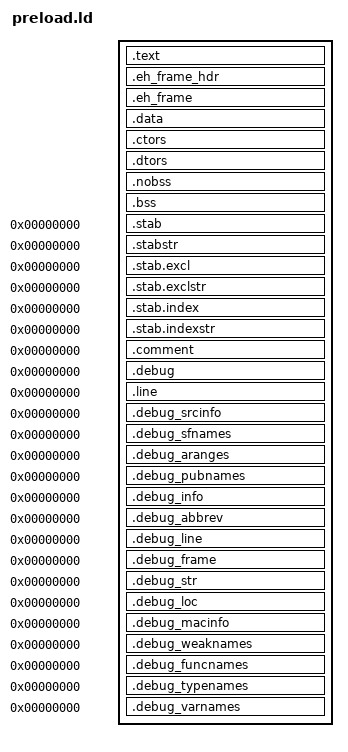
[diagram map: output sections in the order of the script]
SECTIONS
{
    . = 0x80400000;
    . = ALIGN(4096);
    .text :
    {
        KEEP(*(.text.entrypoint))       /* The entry point */
        *(.vectors)
        *(.text)                        /* remaining code */
        *(.text.*)                      /* remaining code */

        *(.rodata)                      /* read-only data (constants) */
        *(.rodata*)
        *(.glue_7)
        *(.glue_7t)
        *(.gnu.linkonce.t*)

        *(COMMON)

        _etext = .;
    }

    . = ALIGN(16);
    .eh_frame_hdr :
    {
         *(.eh_frame_hdr)
         *(.eh_frame_entry)
    }
    .eh_frame : ONLY_IF_RO { KEEP (*(.eh_frame)) }

    . = ALIGN(16);
    .data :
    {
     *(.data)
     *(.data.*)

     *(.data1)
     *(.data1.*)

     . = ALIGN(16);
     _gp = ABSOLUTE(.);     /* Base of small data */

     *(.sdata)
     *(.sdata.*)
    }

    . = ALIGN(16);
    .ctors :
    {
        PROVIDE(__ctors_start__ = .);
        KEEP(*(SORT(.ctors.*)))
        KEEP(*(.ctors))
        PROVIDE(__ctors_end__ = .);
    }

    .dtors :
    {
        PROVIDE(__dtors_start__ = .);
        KEEP(*(SORT(.dtors.*)))
        KEEP(*(.dtors))
        PROVIDE(__dtors_end__ = .);
    }

    . = ALIGN(16);
    .nobss : { *(.nobss) }
    
    . = ALIGN(16);
    __bss_start__ = .;
    __bss_start = .;
    .bss : { *(.bss)}
    . = ALIGN(16);
    __bss_end = .;
    __bss_end__ = .;
    . = ALIGN(16);

    /* Stabs debugging sections.  */
    .stab          0 : { *(.stab) }
    .stabstr       0 : { *(.stabstr) }
    .stab.excl     0 : { *(.stab.excl) }
    .stab.exclstr  0 : { *(.stab.exclstr) }
    .stab.index    0 : { *(.stab.index) }
    .stab.indexstr 0 : { *(.stab.indexstr) }
    .comment       0 : { *(.comment) }
    /* DWARF debug sections.
     * Symbols in the DWARF debugging sections are relative to the beginning
     * of the section so we begin them at 0.  */
    /* DWARF 1 */
    .debug          0 : { *(.debug) }
    .line           0 : { *(.line) }
    /* GNU DWARF 1 extensions */
    .debug_srcinfo  0 : { *(.debug_srcinfo) }
    .debug_sfnames  0 : { *(.debug_sfnames) }
    /* DWARF 1.1 and DWARF 2 */
    .debug_aranges  0 : { *(.debug_aranges) }
    .debug_pubnames 0 : { *(.debug_pubnames) }
    /* DWARF 2 */
    .debug_info     0 : { *(.debug_info .gnu.linkonce.wi.*) }
    .debug_abbrev   0 : { *(.debug_abbrev) }
    .debug_line     0 : { *(.debug_line) }
    .debug_frame    0 : { *(.debug_frame) }
    .debug_str      0 : { *(.debug_str) }
    .debug_loc      0 : { *(.debug_loc) }
    .debug_macinfo  0 : { *(.debug_macinfo) }
    /* SGI/MIPS DWARF 2 extensions */
    .debug_weaknames 0 : { *(.debug_weaknames) }
    .debug_funcnames 0 : { *(.debug_funcnames) }
    .debug_typenames 0 : { *(.debug_typenames) }
    .debug_varnames  0 : { *(.debug_varnames) }
	
    _end = .;
}

__bss_size = (__bss_end - __bss_start)>>3;
